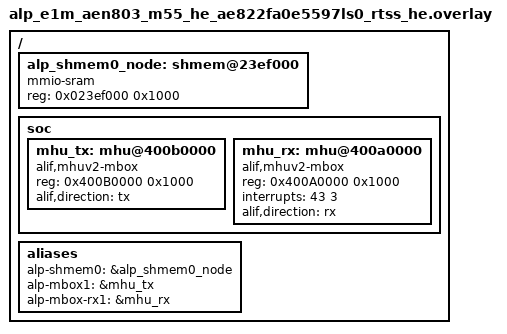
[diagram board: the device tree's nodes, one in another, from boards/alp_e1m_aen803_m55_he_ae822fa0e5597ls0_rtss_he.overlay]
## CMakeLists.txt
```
# SPDX-License-Identifier: Apache-2.0

cmake_minimum_required(VERSION 3.20)

if(DEFINED ENV{ALP_SDK_ROOT})
    set(ALP_SDK_ROOT $ENV{ALP_SDK_ROOT})
else()
    get_filename_component(ALP_SDK_ROOT ${CMAKE_CURRENT_SOURCE_DIR}/../../.. ABSOLUTE)
endif()

find_package(Python3 REQUIRED COMPONENTS Interpreter)

set(_alp_generated ${CMAKE_BINARY_DIR}/generated/alp.conf)
execute_process(
    COMMAND ${Python3_EXECUTABLE} ${ALP_SDK_ROOT}/scripts/alp_project.py
            --input ${CMAKE_CURRENT_SOURCE_DIR}/board.yaml
            --emit zephyr-conf --core m55_hp
            --output ${_alp_generated}
    RESULT_VARIABLE _alp_rv
    OUTPUT_VARIABLE _alp_stdout
    ERROR_VARIABLE  _alp_stderr
)
if(NOT _alp_rv EQUAL 0)
    message(FATAL_ERROR
        "alp_project.py failed (rv=${_alp_rv}); "
        "check ${CMAKE_CURRENT_SOURCE_DIR}/board.yaml.\n"
        "stderr: ${_alp_stderr}")
endif()

list(APPEND EXTRA_CONF_FILE ${_alp_generated})

find_package(Zephyr REQUIRED HINTS $ENV{ZEPHYR_BASE})
project(mproc_mailbox LANGUAGES C)

target_sources(app PRIVATE src/main.c)
```

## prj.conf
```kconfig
# SPDX-License-Identifier: Apache-2.0
#
# Otherwise empty by design.  The build's effective Kconfig is
# build/generated/alp.conf -- emitted from this app's board.yaml
# by `tan build` and layered over this file via
# EXTRA_CONF_FILE (see scripts/gen_example_alp_conf.py). board.yaml's `ipc:` block (kind:
# raw_shmem, endpoints: [m55_hp, m55_he]) now makes kconfig.py's
# `_emit_cross_core_shmem_cache` emit CONFIG_DCACHE=n into the generated
# conf too (PR #1080 follow-up -- this used to be the Ethos-U inference
# branch's job alone).  The line below is kept anyway: it predates the
# generator support, is bench-proven, and removing a hand-written line in
# the same change that adds the generator path would make it impossible
# to tell which one was doing the work if something regressed.  Dropping
# it is a clean follow-up once the generator path is trusted.

# Shared global-SRAM0 mailbox is read/written by BOTH M55 cores, each with its
# own D-cache -> the region must be coherent. Disable the D-cache (the AEN
# SRAM-coherency precedent: the NPU apps do the same) so cross-core reads see
# the other core's writes without explicit clean/invalidate. (A cache-on variant
# would sys_cache_data_flush_range on the writer + invd_range on the reader, on
# silicon where the D-cache can be enabled at all.)
CONFIG_DCACHE=n
```

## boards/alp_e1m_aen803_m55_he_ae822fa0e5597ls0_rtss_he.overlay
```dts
/*
 * Copyright (c) 2026 Alp Lab AB
 * SPDX-License-Identifier: Apache-2.0
 *
 * mproc-mailbox -- AEN M55 overlay (identical on M55-HP and M55-HE).
 *
 * Wires the two DT aliases src/backends/mproc/zephyr_drv.c resolves:
 *
 *   alp-shmem0   the 4 KiB raw_shmem carve-out the orchestrator resolves
 *                for board.yaml's `ipc:` block (`--emit system-manifest`:
 *                0x023ef000, size 0x1000, in the SoM's `sram_ipc` row of
 *                global SRAM0).  SRAM0 (Alif DFP AE822FA0E5597
 *                soc_features.h: SOC_FEAT_BULK_SRAM0_BASE 0x02000000)
 *                is the same address from both cores.  The orchestrator
 *                and this overlay must agree on the address.
 *   alp-mbox1    the MHUv2 sender frame (0x400B0000).  An MHUv2 frame is
 *                one-directional, so the receiver frame (0x400A0000,
 *                IRQ 43) is aliased as alp-mbox-rx1; the backend sends on
 *                the first and takes the reply callback on the second.
 *
 * The MHUv2 is doorbell-only (its send rejects a payload), so
 * src/backends/mproc/zephyr_drv.c carries each alp_mbox_send() payload in
 * the last 64 bytes of alp-shmem0 and rings the doorbell bit named by
 * `.channel` (1 = the SoM's `app` mailbox channel, matching
 * ALP_IPC_ALP_SHMEM0_MBOX_CH in the emitted <alp/system_ipc.h>).  Keep
 * the example's own shmem offsets clear of that tail slot.
 *
 * MHU addresses and IRQ are the bench-proven pair from aen-rpc-pingpong
 * (Alif DFP rtss_hp/soc.h: MHU_M55HE_M55HP_1_RX_BASE 0x400A0000,
 * MHU_M55HE_M55HP_1_RX_IRQn 43); each core's 0x400B0000 is its own
 * "TX to the peer" alias.
 */

/ {
	alp_shmem0_node: shmem@23ef000 {
		compatible = "mmio-sram";
		reg = <0x023ef000 0x1000>;
		status = "okay";
	};

	soc {
		mhu_tx: mhu@400b0000 {
			compatible = "alif,mhuv2-mbox";
			reg = <0x400B0000 0x1000>;
			alif,direction = "tx";
			#mbox-cells = <1>;
			status = "okay";
		};

		mhu_rx: mhu@400a0000 {
			compatible = "alif,mhuv2-mbox";
			reg = <0x400A0000 0x1000>;
			interrupts = <43 3>;
			alif,direction = "rx";
			#mbox-cells = <1>;
			status = "okay";
		};
	};

	aliases {
		alp-shmem0   = &alp_shmem0_node;
		alp-mbox1    = &mhu_tx;
		alp-mbox-rx1 = &mhu_rx;
	};
};
```

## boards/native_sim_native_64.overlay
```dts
/*
 * Copyright 2026 Alp Lab AB
 * SPDX-License-Identifier: Apache-2.0
 *
 * Overlay declaring alp-shmem0 for the mproc-mailbox example so the
 * HP-side native_sim build resolves "alp_shmem0" through the new
 * DT-anchored lookup path (commit 2e9deec, v0.7).  native_sim never
 * dereferences the address; alp_shmem_view just reports the
 * DT-anchored base + size verbatim and the example's memcpy is
 * skipped on the !CONFIG_BOARD_NATIVE_SIM branch.
 *
 * On real AEN silicon the alp-shmem0 alias must point at a
 * reserved-memory carve-out shared between the M55-HP and M55-HE
 * images.  The orchestrator (scripts/alp_orchestrate.py) emits the
 * per-core overlay with the matching alias when the board.yaml v2
 * declares an ipc[] block; until that ships customers can declare
 * the alias by hand in a board overlay following this same shape:
 *
 *     / {
 *         alp_shmem0_node: shmem@<carve_out_addr> {
 *             compatible = "mmio-sram";
 *             reg = <0x<addr> 0x<size>>;
 *             status = "okay";
 *         };
 *         aliases { alp-shmem0 = &alp_shmem0_node; };
 *     };
 */

/ {
    alp_shmem0_node: shmem@70000000 {
        compatible = "mmio-sram";
        reg = <0x70000000 0x1000>;
        status = "okay";
    };

    aliases {
        alp-shmem0 = &alp_shmem0_node;
    };
};
```

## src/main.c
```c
/*
 * Copyright 2026 Alp Lab AB
 * SPDX-License-Identifier: Apache-2.0
 *
 * mproc-mailbox -- M55-HP <-> M55-HE shared-memory mailbox
 * roundtrip on AEN (Alif Ensemble dual-Cortex-M55 silicon).
 *
 * The pattern this example shows
 * ==============================
 *
 * Two Cortex-M55 cores share a small region of non-cached
 * SRAM + a hardware mailbox + a hardware semaphore.  An app on
 * the M55-HP (the "application" core) sends a payload to the
 * M55-HE (the "high-efficiency" peer) and waits for a reply.
 *
 *   1. HP owns the application: Wi-Fi, MQTT, UI.
 *   2. HE owns offloadable work: PDM/audio DSP, slow sensor
 *      polling, inference pre/post-processing.
 *   3. Mailbox + shared memory are how HP hands work to HE and
 *      collects results.
 *
 * The SDK exposes this through <alp/mproc.h>.  Same API on AEN
 * (HP<->HE) and on V2N (Cortex-A55 <-> Cortex-M33); the
 * backend dispatches to the silicon's hardware mailbox.
 *
 * What you'll see in this example
 * ===============================
 *
 *   [mproc] init mbox + shmem
 *   [mproc] sending payload  "hello-from-HP" (13 bytes)
 *   [mproc] HE replied via mbox callback
 *   [mproc] HE replied       "echo: hello-from-HP" (19 bytes)
 *   [mproc] done
 *
 * Under native_sim there's no peer core; the example exercises
 * just the HP-side init + the framing-encode path + `done`.
 * Real-silicon runs both halves.
 *
 * Peer firmware
 * =============
 *
 * The HE-side application lives at
 * `examples/multicore/mproc-mailbox/peer/main.c`.  Both halves build
 * standalone via `west build`, and `board.yaml` declaring both
 * `m55_hp` and `m55_he` as real project cores means one `tan build`
 * already produces both images through the orchestrator's existing
 * multi-slice path -- no sysbuild involved.
 */

#include <stdio.h>
#include <string.h>

#include "alp/mproc.h"
#include "alp/peripheral.h"

/* Region name resolved against the alp-shmemN DT aliases in the
 * board overlay -- here, alp-shmem0 in boards/<board>.overlay or
 * the orchestrator-emitted carve-out for AEN dual-core builds. */
#define SHMEM_REGION_NAME "alp_shmem0"
#define SHMEM_REGION_SIZE 512u
#define MBOX_CHANNEL      1u /* the SoM's `app` mailbox channel; ALP_IPC_ALP_SHMEM0_MBOX_CH */
#define REQUEST_OFFSET    0u
#define RESPONSE_OFFSET   256u /* gap from request so the two never overlap */
#define MAX_PAYLOAD       128u

static const char *PAYLOAD = "hello-from-HP";

static struct {
	volatile bool   got_reply;
	volatile size_t reply_offset;
	volatile size_t reply_len;
} g_state;

/* Mailbox inbound-message callback.  Fires when the HE peer
 * signals back with the (offset, length) tuple naming the
 * staged echo response.  Runs on the SDK's mbox thread; we
 * just stash the values so main() can drain them. */
static void mbox_inbound(uint32_t channel, const void *data, size_t len, void *user)
{
	(void)channel;
	(void)user;
	if (len < 8u) return;
	const uint8_t *b = data;
	g_state.reply_offset =
	    (size_t)b[0] | ((size_t)b[1] << 8) | ((size_t)b[2] << 16) | ((size_t)b[3] << 24);
	g_state.reply_len =
	    (size_t)b[4] | ((size_t)b[5] << 8) | ((size_t)b[6] << 16) | ((size_t)b[7] << 24);
	g_state.got_reply = true;
}

int main(void)
{
	printf("[mproc] init mbox + shmem\n");

	const alp_shmem_config_t shmem_cfg = {
		.name = SHMEM_REGION_NAME,
		.size = SHMEM_REGION_SIZE,
	};
	alp_shmem_t *shmem = alp_shmem_open(&shmem_cfg);

	const alp_mbox_config_t mbox_cfg = {
		.channel = MBOX_CHANNEL,
		.peer    = ALP_CORE_M55_HE,
	};
	alp_mbox_t *mbox = alp_mbox_open(&mbox_cfg);

	if (shmem == NULL || mbox == NULL) {
		printf("[mproc]   open failed: last_err=%d\n", (int)alp_last_error());
		goto done;
	}

	/* Get a pointer view of the shared region.  Both cores see
     * the same physical bytes; the region is non-cacheable,
     * so no cache flush is needed. */
	void  *shmem_base = NULL;
	size_t shmem_size = 0u;
	if (alp_shmem_view(shmem, &shmem_base, &shmem_size) != ALP_OK) {
		printf("[mproc]   shmem view failed\n");
		goto teardown;
	}
	if (shmem_size < RESPONSE_OFFSET + MAX_PAYLOAD) {
		printf("[mproc]   shmem too small (%zu)\n", shmem_size);
		goto teardown;
	}

	/* Stage the payload at REQUEST_OFFSET in the shared region.
     * memcpy is the right primitive here -- the SDK's shmem
     * surface gives back a raw pointer + size and trusts the
     * caller to write through it. */
	const size_t payload_len = strlen(PAYLOAD);
	memcpy((uint8_t *)shmem_base + REQUEST_OFFSET, PAYLOAD, payload_len);

	/* Register the receive callback BEFORE sending.  The Zephyr backend
     * only enables the RX channel inside alp_mbox_set_callback(), and the
     * peer replies from its mailbox IRQ within microseconds of our send;
     * a callback registered after the send would drop that reply and
     * report a healthy peer as dead.  The peer sends back via the same
     * mbox; the callback drains the (offset, length) tuple naming the
     * echo response. */
	if (alp_mbox_set_callback(mbox, mbox_inbound, NULL) != ALP_OK) {
		printf("[mproc]   set_callback failed\n");
		goto teardown;
	}

	/* Send the mailbox notification.  Payload here is the
     * `(offset, length)` tuple that points at the staged bytes
     * in shmem; the peer reads the actual data through its own
     * shmem view. */
	uint8_t mbox_msg[8] = {
		(uint8_t)REQUEST_OFFSET, 0, 0, 0, /* offset (LE u32) */
		(uint8_t)payload_len,    0, 0, 0, /* length (LE u32) */
	};
	if (alp_mbox_send(mbox, mbox_msg, sizeof(mbox_msg), 100u) != ALP_OK) {
		printf("[mproc]   mbox send failed\n");
		goto teardown;
	}
	printf("[mproc] sending payload  \"%s\" (%u bytes)\n", PAYLOAD, (unsigned)payload_len);

#ifdef CONFIG_BOARD_NATIVE_SIM
	printf("[mproc]   native_sim: no peer core; skipping reply wait\n");
#else
	/* Poll for the reply.  On HiL the mailbox-ISR-driven
     * callback flips g_state.got_reply within ~1 ms of the
     * peer's send. */
	for (int i = 0; i < 100 && !g_state.got_reply; ++i) {
		alp_delay_ms(10);
	}
	if (!g_state.got_reply) {
		printf("[mproc]   reply timeout (peer not running?)\n");
		goto teardown;
	}
	printf("[mproc] HE replied via mbox callback\n");

	/* The (offset, length) tuple comes from the other core, so treat it as
     * untrusted: a desynced peer image must not make us read outside the
     * shared region.  Clamp the length first, then require the whole
     * [offset, offset + len) window to sit inside shmem_size (written as a
     * subtraction so offset + len cannot wrap). */
	const size_t reply_offset = g_state.reply_offset;
	size_t       reply_len    = g_state.reply_len;
	if (reply_len > MAX_PAYLOAD) reply_len = MAX_PAYLOAD;
	if (reply_offset > shmem_size || reply_len > shmem_size - reply_offset) {
		printf("[mproc]   reply out of range (offset=%zu len=%zu)\n", reply_offset, reply_len);
		goto teardown;
	}
	char reply_buf[MAX_PAYLOAD + 1];
	memcpy(reply_buf, (uint8_t *)shmem_base + reply_offset, reply_len);
	reply_buf[reply_len] = '\0';
	printf("[mproc] HE replied       \"%s\" (%u bytes)\n", reply_buf, (unsigned)reply_len);
#endif

teardown:
	alp_mbox_close(mbox);
	alp_shmem_close(shmem);

done:
	printf("[mproc] done\n");
	return 0;
}
```
